# ADUCM360 register map
Vendor: Analog Devices; Series: ARMCM3; File version: 0.7
CPU: CM3 r2p0, little endian, no MPU, no FPU, 3 interrupt priority bits
Registers are 16-bit, read-write, no defined reset value unless marked. A register's access mark holds for its fields unless they carry their own. Offsets are from the block's base; [hi:lo] are bit positions; {n}, {i} and the like mark numbered series.

## ADI_PWM — Pulse Width Modulation
Base 0x40001000
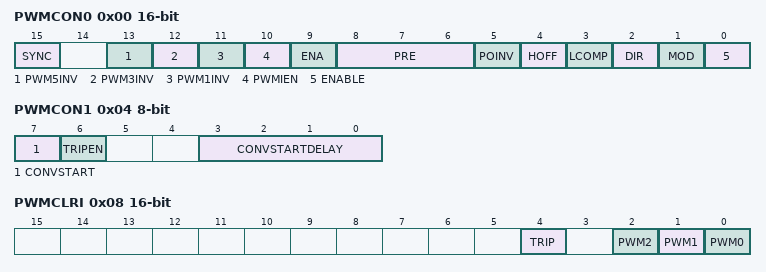
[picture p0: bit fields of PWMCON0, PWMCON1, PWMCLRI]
0x00 PWMCON0 — PWM Control register
  [15] SYNC — PWM Synchronization
    0=DIS; 1=EN
  [13] PWM5INV — Inversion of PWM output
    0=DIS; 1=EN
  [12] PWM3INV — Inversion of PWM output
    0=DIS; 1=EN
  [11] PWM1INV — Inversion of PWM output
    0=DIS; 1=EN
  [10] PWMIEN — Enables PWM interrupts
    0=DIS; 1=EN
  [9] ENA — enable PWM outputs
    0=DIS; 1=EN
  [8:6] PRE — PWM Clock Prescaler
  [5] POINV — Invert all PWM outputs
    0=DIS; 1=EN
  [4] HOFF — High Side Off
    0=DIS; 1=EN
  [3] LCOMP — Load Compare Registers
    0=DIS; 1=EN
  [2] DIR — Direction Control
    0=DIS; 1=EN
  [1] MOD — Enables H-Bridge Mode
    0=DIS; 1=EN
  [0] ENABLE — Enables all PWM outputs
    0=DIS; 1=EN
0x04 PWMCON1 8-bit — Trip control register
  [7] CONVSTART — Enable adc conversion start from pwm
    0=DIS; 1=EN
  [6] TRIPEN — Enable PWM trip functionality
    0=DIS; 1=EN
  [3:0] CONVSTARTDELAY — ADC conversion start delay configuration
0x08 PWMCLRI — PWM interrupt clear. Write to this register clears the latched PWM interrupt.
  [all] fields
    0=DIS; 1=EN
  [4] TRIP — Clear the latched trip interrupt
  [2] PWM2 — Clear the latched PWM2 interrupt
  [1] PWM1 — Clear the latched PWM1 interrupt
  [0] PWM0 — Clear the latched PWM0 interrupt
{0x10+0x10*i} PWM{i}COM0 (i=0..2) — Compare Register 0 for PWM{2i} and PWM{2i+1}
{0x14+0x10*i} PWM{i}COM1 (i=0..2) — Compare Register 1 for PWM{2i} and PWM{2i+1}
{0x18+0x10*i} PWM{i}COM2 (i=0..2) — Compare Register 2 for PWM{2i} and PWM{2i+1}
{0x1C+0x10*i} PWM{i}LEN (i=0..2) — Period Value register for PWM{2i} and PWM{2i+1}

## ADI_PWRCTL — Power Management Unit
Base 0x40002400
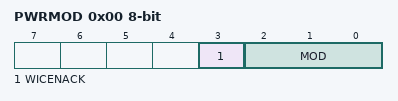
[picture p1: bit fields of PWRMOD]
0x00 PWRMOD 8-bit — Power modes register
  [3] WICENACK — For Deepsleep mode only
    0=DIS; 1=EN
  [2:0] MOD — Power Mode
    0=FULLACTIVE; 1=MCUHALT; 2=PERHALT; 3=SYSHALT; 4=TOTALHALT; 5=HIBERNATE
0x04 PWRKEY — Key protection for the PWRMOD register.
  [15:0] VALUE — Key value
    0x4859=KEY1; 0xF27B=KEY2

## ADI_RESET — Reset
Base 0x40002440
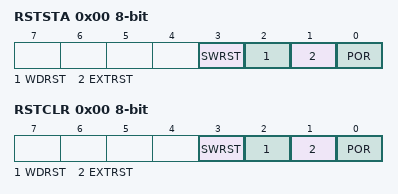
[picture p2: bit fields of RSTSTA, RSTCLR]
0x00 RSTSTA 8-bit — Reset Status
  [all] fields
    0=CLR; 1=SET
  [3] SWRST — Software reset status bit
  [2] WDRST — Watchdog reset status bit
  [1] EXTRST — External reset status bit
  [0] POR — Power-on reset status bit
0x00 RSTCLR 8-bit (alternate view of RSTSTA) — Reset Status Clear
  [all] fields
    0=DIS; 1=EN
  [3] SWRST — Software reset status bit
  [2] WDRST — Watchdog reset status bit
  [1] EXTRST — External reset status bit
  [0] POR — Power-on reset status bit

## ADI_INTERRUPT — Interrupts
Base 0x40002420
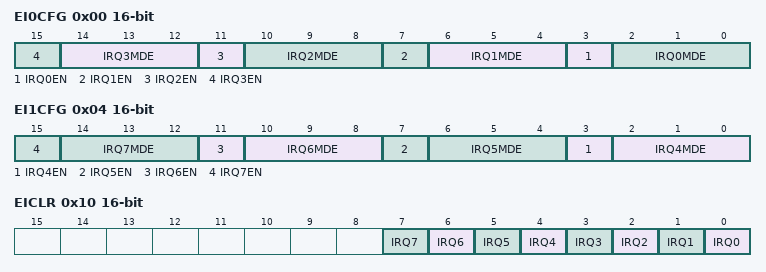
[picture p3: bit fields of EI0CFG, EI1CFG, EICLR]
0x00 EI0CFG — External Interrupt configuration register 0
  [4n+3] IRQ{n}EN (n=0..3) — External Interrupt {n} Enable
    0=DIS; 1=EN
  [14:12] IRQ3MDE — External Interrupt 0 Mode
    0=RISE; 1=FALL; 2=RISEORFALL; 3=HIGHLEVEL; 4=LOWLEVEL
  [10:8] IRQ2MDE — External Interrupt 2 Mode
    0=RISE; 1=FALL; 2=RISEORFALL; 3=HIGHLEVEL; 4=LOWLEVEL
  [6:4] IRQ1MDE — External Interrupt 1 Mode
    0=RISE; 1=FALL; 2=RISEORFALL; 3=HIGHLEVEL; 4=LOWLEVEL
  [2:0] IRQ0MDE — External Interrupt 0 Mode
    0=RISE; 1=FALL; 2=RISEORFALL; 3=HIGHLEVEL; 4=LOWLEVEL
0x04 EI1CFG — External Interrupt configuration register 1
  [4n-13] IRQ{n}EN (n=4..7) — External Interrupt {n} Enable
    0=DIS; 1=EN
  [4n-14:4n-16] IRQ{n}MDE (n=4..7) — External Interrupt {n} Mode
    0=RISE; 1=FALL; 2=RISEORFALL; 3=HIGHLEVEL; 4=LOWLEVEL
0x10 EICLR — External Interrupts Clear register
  [all] fields
    1=CLR
  [n] IRQ{n} (n=0..7) — Clears External interrupt {n} internal flag

## ADI_WDT — Watchdog Timer
Base 0x40002580
0x00 T3LD — Load value.
  [15:0] VALUE — Current Value
0x04 T3VAL — "Current count value, read only."
  [15:0] VALUE — Current Value
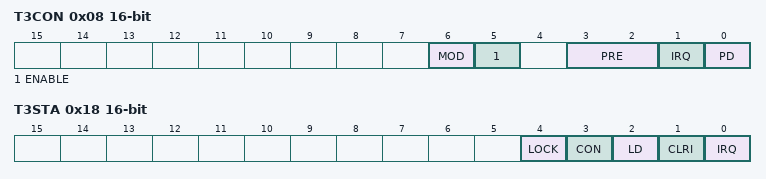
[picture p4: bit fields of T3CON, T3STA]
0x08 T3CON — Control Register
  [6] MOD — Mode
    0=FREERUN; 1=PERIODIC
  [5] ENABLE
    0=DIS; 1=EN
  [3:2] PRE — Prescaler
    0=DIV1; 1=DIV16; 2=DIV256; 3=DIV4096
  [1] IRQ — Timer Interrupt ,
    0=DIS; 1=EN
  [0] PD — Power down clear
    0=DIS; 1=EN
0x0C T3CLRI — "Clear interrupt, write only."
  [15:0] VALUE — Clear Watchdog
    0xCCCC=CLR
0x18 T3STA — "Status register, read only."
  [all] fields
    0=CLR; 1=SET
  [4] LOCK — Lock status bit
  [3] CON — T3CON write sync in progress
  [2] LD — T3LD write sync in progress
  [1] CLRI — T3CLRI write sync in progress
  [0] IRQ — Interrupt Pending
